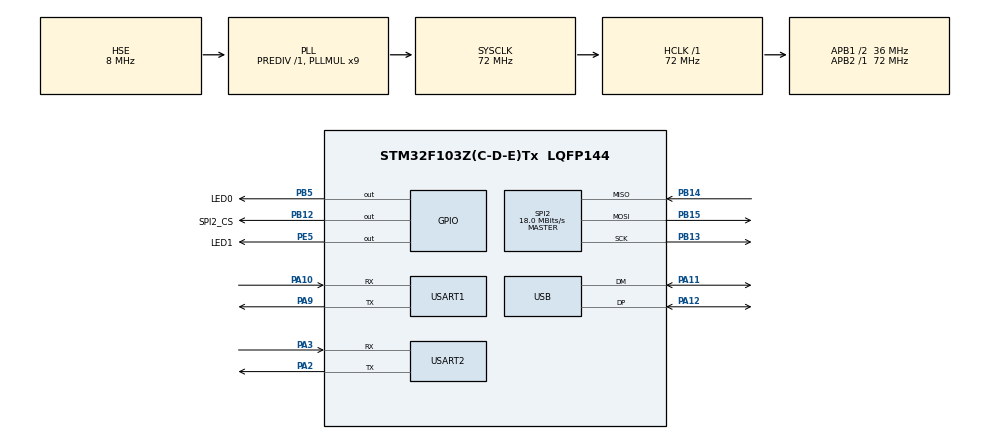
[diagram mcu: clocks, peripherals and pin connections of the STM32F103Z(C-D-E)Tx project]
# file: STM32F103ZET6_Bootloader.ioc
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Dma.Request0=USART1_RX
Dma.Request1=USART1_TX
Dma.Request2=USART2_RX
Dma.Request3=USART2_TX
Dma.USART1_RX.0.Direction=DMA_PERIPH_TO_MEMORY
Dma.USART1_RX.0.Instance=DMA1_Channel5
Dma.USART1_RX.0.MemDataAlignment=DMA_MDATAALIGN_BYTE
Dma.USART1_RX.0.MemInc=DMA_MINC_ENABLE
Dma.USART1_RX.0.Mode=DMA_NORMAL
Dma.USART1_RX.0.PeriphDataAlignment=DMA_PDATAALIGN_BYTE
Dma.USART1_RX.0.PeriphInc=DMA_PINC_DISABLE
Dma.USART1_RX.0.Priority=DMA_PRIORITY_LOW
Dma.USART1_TX.1.Direction=DMA_MEMORY_TO_PERIPH
Dma.USART1_TX.1.Instance=DMA1_Channel4
Dma.USART1_TX.1.MemDataAlignment=DMA_MDATAALIGN_BYTE
Dma.USART1_TX.1.MemInc=DMA_MINC_ENABLE
Dma.USART1_TX.1.Mode=DMA_NORMAL
Dma.USART1_TX.1.PeriphDataAlignment=DMA_PDATAALIGN_BYTE
Dma.USART1_TX.1.PeriphInc=DMA_PINC_DISABLE
Dma.USART1_TX.1.Priority=DMA_PRIORITY_LOW
Dma.USART2_RX.2.Direction=DMA_PERIPH_TO_MEMORY
Dma.USART2_RX.2.Instance=DMA1_Channel6
Dma.USART2_RX.2.MemDataAlignment=DMA_MDATAALIGN_BYTE
Dma.USART2_RX.2.MemInc=DMA_MINC_ENABLE
Dma.USART2_RX.2.Mode=DMA_NORMAL
Dma.USART2_RX.2.PeriphDataAlignment=DMA_PDATAALIGN_BYTE
Dma.USART2_RX.2.PeriphInc=DMA_PINC_DISABLE
Dma.USART2_RX.2.Priority=DMA_PRIORITY_LOW
Dma.USART2_TX.3.Direction=DMA_MEMORY_TO_PERIPH
Dma.USART2_TX.3.Instance=DMA1_Channel7
Dma.USART2_TX.3.MemDataAlignment=DMA_MDATAALIGN_BYTE
Dma.USART2_TX.3.MemInc=DMA_MINC_ENABLE
Dma.USART2_TX.3.Mode=DMA_NORMAL
Dma.USART2_TX.3.PeriphDataAlignment=DMA_PDATAALIGN_BYTE
Dma.USART2_TX.3.PeriphInc=DMA_PINC_DISABLE
Dma.USART2_TX.3.Priority=DMA_PRIORITY_LOW
FREERTOS.Tasks01=defaultTask,24,3072,StartDefaultTask,Default,NULL,Static,defaultTaskBuffer,defaultTaskControlBlock
FREERTOS.configTOTAL_HEAP_SIZE=5120
Mcu.Family=STM32F1
Mcu.Name=STM32F103Z(C-D-E)Tx
Mcu.Package=LQFP144
NVIC.DMA1_Channel4_IRQn=true\:5\:0\:false\:false\:true\:true\:false\:true
NVIC.DMA1_Channel5_IRQn=true\:5\:0\:false\:false\:true\:true\:false\:true
NVIC.DMA1_Channel6_IRQn=true\:5\:0\:false\:false\:true\:true\:false\:true
NVIC.DMA1_Channel7_IRQn=true\:5\:0\:false\:false\:true\:true\:false\:true
NVIC.PriorityGroup=NVIC_PRIORITYGROUP_4
NVIC.SPI2_IRQn=true\:5\:0\:false\:false\:true\:true\:true\:true
NVIC.TIM1_UP_IRQn=true\:0\:0\:false\:false\:true\:false\:false\:true
NVIC.TimeBase=TIM1_UP_IRQn
NVIC.TimeBaseIP=TIM1
NVIC.USART1_IRQn=true\:5\:0\:false\:false\:true\:true\:true\:true
NVIC.USART2_IRQn=true\:5\:0\:false\:false\:true\:true\:true\:true
NVIC.USB_LP_CAN1_RX0_IRQn=true\:5\:0\:false\:false\:true\:true\:false\:true
OSC_IN.Mode=HSE-External-Oscillator
OSC_IN.Signal=RCC_OSC_IN
OSC_OUT.Mode=HSE-External-Oscillator
OSC_OUT.Signal=RCC_OSC_OUT
PA10.GPIO_PuPd=GPIO_PULLUP
PA10.Mode=Asynchronous
PA10.Signal=USART1_RX
PA11.Mode=Device
PA11.Signal=USB_DM
PA12.Mode=Device
PA12.Signal=USB_DP
PA13.Mode=JTAG_5_pins
PA13.Signal=SYS_JTMS-SWDIO
PA14.Mode=JTAG_5_pins
PA14.Signal=SYS_JTCK-SWCLK
PA15.Mode=JTAG_5_pins
PA15.Signal=SYS_JTDI
PA2.Mode=Asynchronous
PA2.Signal=USART2_TX
PA3.GPIO_PuPd=GPIO_PULLUP
PA3.Mode=Asynchronous
PA3.Signal=USART2_RX
PA9.Mode=Asynchronous
PA9.Signal=USART1_TX
PB12.GPIO_Label=SPI2_CS
PB12.Signal=GPIO_Output
PB13.Mode=Full_Duplex_Master
PB13.Signal=SPI2_SCK
PB14.Mode=Full_Duplex_Master
PB14.Signal=SPI2_MISO
PB15.Mode=Full_Duplex_Master
PB15.Signal=SPI2_MOSI
PB3.Mode=JTAG_5_pins
PB3.Signal=SYS_JTDO-TRACESWO
PB4.Mode=JTAG_5_pins
PB4.Signal=SYS_NJTRST
PB5.GPIO_Label=LED0
PB5.Signal=GPIO_Output
PC14-OSC32_IN.Mode=LSE-External-Oscillator
PC14-OSC32_IN.Signal=RCC_OSC32_IN
PC15-OSC32_OUT.Mode=LSE-External-Oscillator
PC15-OSC32_OUT.Signal=RCC_OSC32_OUT
PE5.GPIO_Label=LED1
PE5.Signal=GPIO_Output
ProjectManager.HeapSize=0x1000
ProjectManager.StackSize=0x5000
ProjectManager.TargetToolchain=EWARM V8.32
RCC.AHBFreq_Value=72000000
RCC.APB1CLKDivider=RCC_HCLK_DIV2
RCC.APB1Freq_Value=36000000
RCC.APB1TimFreq_Value=72000000
RCC.APB2Freq_Value=72000000
RCC.APB2TimFreq_Value=72000000
RCC.HCLKFreq_Value=72000000
RCC.PLLMUL=RCC_PLL_MUL9
RCC.SYSCLKFreq_VALUE=72000000
RCC.SYSCLKSource=RCC_SYSCLKSOURCE_PLLCLK
RCC.USBFreq_Value=48000000
RCC.USBPrescaler=RCC_USBCLKSOURCE_PLL_DIV1_5
RTC.Format=RTC_FORMAT_BIN
SPI2.CLKPhase=SPI_PHASE_2EDGE
SPI2.CLKPolarity=SPI_POLARITY_HIGH
SPI2.CalculateBaudRate=18.0 MBits/s
SPI2.Direction=SPI_DIRECTION_2LINES
SPI2.Mode=SPI_MODE_MASTER
SPI2.VirtualType=VM_MASTER
USART1.VirtualMode=VM_ASYNC
USART2.VirtualMode=VM_ASYNC
USB_DEVICE.CLASS_NAME_FS=CUSTOM_HID
USB_DEVICE.VirtualMode=CustomHid
USB_DEVICE.VirtualModeFS=Custom_Hid_FS
VP_FREERTOS_VS_CMSIS_V2.Mode=CMSIS_V2
VP_RTC_VS_RTC_Activate.Mode=RTC_Enabled
VP_RTC_VS_RTC_Calendar.Mode=RTC_Calendar
VP_SYS_VS_tim1.Mode=TIM1
VP_USB_DEVICE_VS_USB_DEVICE_CUSTOM_HID_FS.Mode=CUSTOM_HID_FS
board=custom

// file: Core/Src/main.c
/* USER CODE BEGIN Header */
/**
  ******************************************************************************
  * @file           : main.c
  * @brief          : Main program body
  ******************************************************************************
  * @attention
  *
  * <h2><center>&copy; Copyright (c) 2021 STMicroelectronics.
  * All rights reserved.</center></h2>
  *
  * This software component is licensed by ST under Ultimate Liberty license
  * SLA0044, the "License"; You may not use this file except in compliance with
  * the License. You may obtain a copy of the License at:
  *                             www.st.com/SLA0044
  *
  ******************************************************************************
  */
/* USER CODE END Header */
#include "main.h"
#include "cmsis_os.h"
#include "dma.h"
#include "rtc.h"
#include "spi.h"
#include "usart.h"
#include "usb_device.h"
#include "gpio.h"

void SystemClock_Config(void);
void MX_FREERTOS_Init(void);

int main(void)
{

  /* MCU Configuration--------------------------------------------------------*/

  /* Reset of all peripherals, Initializes the Flash interface and the Systick. */
  HAL_Init();

  /* Configure the system clock */
  SystemClock_Config();

  /* Initialize all configured peripherals */
  MX_GPIO_Init();
  MX_DMA_Init();
  MX_USART1_UART_Init();
  MX_RTC_Init();
  MX_SPI2_Init();
  MX_USART2_UART_Init();
  /* USER CODE BEGIN 2 */
  User_Main_Init();
  /* USER CODE END 2 */

  /* Init scheduler */
  osKernelInitialize();  /* Call init function for freertos objects (in freertos.c) */
  MX_FREERTOS_Init();
  /* Start scheduler */
  osKernelStart();

  /* We should never get here as control is now taken by the scheduler */
  /* Infinite loop */
  while (1)
  {

  }
}

void SystemClock_Config(void)
{
  RCC_OscInitTypeDef RCC_OscInitStruct = {0};
  RCC_ClkInitTypeDef RCC_ClkInitStruct = {0};
  RCC_PeriphCLKInitTypeDef PeriphClkInit = {0};

  /** Initializes the RCC Oscillators according to the specified parameters
  * in the RCC_OscInitTypeDef structure.
  */
  RCC_OscInitStruct.OscillatorType = RCC_OSCILLATORTYPE_LSI|RCC_OSCILLATORTYPE_HSE;
  RCC_OscInitStruct.HSEState = RCC_HSE_ON;
  RCC_OscInitStruct.HSEPredivValue = RCC_HSE_PREDIV_DIV1;
  RCC_OscInitStruct.HSIState = RCC_HSI_ON;
  RCC_OscInitStruct.LSIState = RCC_LSI_ON;
  RCC_OscInitStruct.PLL.PLLState = RCC_PLL_ON;
  RCC_OscInitStruct.PLL.PLLSource = RCC_PLLSOURCE_HSE;
  RCC_OscInitStruct.PLL.PLLMUL = RCC_PLL_MUL9;
  if (HAL_RCC_OscConfig(&RCC_OscInitStruct) != HAL_OK)
  {
    Error_Handler();
  }
  /** Initializes the CPU, AHB and APB buses clocks
  */
  RCC_ClkInitStruct.ClockType = RCC_CLOCKTYPE_HCLK|RCC_CLOCKTYPE_SYSCLK
                              |RCC_CLOCKTYPE_PCLK1|RCC_CLOCKTYPE_PCLK2;
  RCC_ClkInitStruct.SYSCLKSource = RCC_SYSCLKSOURCE_PLLCLK;
  RCC_ClkInitStruct.AHBCLKDivider = RCC_SYSCLK_DIV1;
  RCC_ClkInitStruct.APB1CLKDivider = RCC_HCLK_DIV2;
  RCC_ClkInitStruct.APB2CLKDivider = RCC_HCLK_DIV1;

  if (HAL_RCC_ClockConfig(&RCC_ClkInitStruct, FLASH_LATENCY_2) != HAL_OK)
  {
    Error_Handler();
  }
  PeriphClkInit.PeriphClockSelection = RCC_PERIPHCLK_RTC|RCC_PERIPHCLK_USB;
  PeriphClkInit.RTCClockSelection = RCC_RTCCLKSOURCE_LSI;
  PeriphClkInit.UsbClockSelection = RCC_USBCLKSOURCE_PLL_DIV1_5;
  if (HAL_RCCEx_PeriphCLKConfig(&PeriphClkInit) != HAL_OK)
  {
    Error_Handler();
  }
}

 /**
  * @brief  Period elapsed callback in non blocking mode
  * @note   This function is called  when TIM1 interrupt took place, inside
  * HAL_TIM_IRQHandler(). It makes a direct call to HAL_IncTick() to increment
  * a global variable "uwTick" used as application time base.
  * @param  htim : TIM handle
  * @retval None
  */
void HAL_TIM_PeriodElapsedCallback(TIM_HandleTypeDef *htim)
{
  if (htim->Instance == TIM1) {
    HAL_IncTick();
  }
}

void Error_Handler(void)
{
  __disable_irq();
  while (1)
  {
  }
}

/************************ (C) COPYRIGHT STMicroelectronics *****END OF FILE****/

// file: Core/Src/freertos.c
/* USER CODE BEGIN Header */
/**
  ******************************************************************************
  * File Name          : freertos.c
  * Description        : Code for freertos applications
  ******************************************************************************
  * @attention
  *
  * <h2><center>&copy; Copyright (c) 2021 STMicroelectronics.
  * All rights reserved.</center></h2>
  *
  * This software component is licensed by ST under Ultimate Liberty license
  * SLA0044, the "License"; You may not use this file except in compliance with
  * the License. You may obtain a copy of the License at:
  *                             www.st.com/SLA0044
  *
  ******************************************************************************
  */
/* USER CODE END Header */

#include "FreeRTOS.h"
#include "task.h"
#include "main.h"
#include "cmsis_os.h"

typedef StaticTask_t osStaticThreadDef_t;

/* Definitions for defaultTask */
osThreadId_t defaultTaskHandle;
uint32_t defaultTaskBuffer[ 3072 ];
osStaticThreadDef_t defaultTaskControlBlock;
const osThreadAttr_t defaultTask_attributes = {
  .name = "defaultTask",
  .cb_mem = &defaultTaskControlBlock,
  .cb_size = sizeof(defaultTaskControlBlock),
  .stack_mem = &defaultTaskBuffer[0],
  .stack_size = sizeof(defaultTaskBuffer),
  .priority = (osPriority_t) osPriorityNormal,
};

void StartDefaultTask(void *argument);

extern void MX_USB_DEVICE_Init(void);
void MX_FREERTOS_Init(void); /* (MISRA C 2004 rule 8.1) */

void MX_FREERTOS_Init(void) {

  /* Create the thread(s) */
  /* creation of defaultTask */
  defaultTaskHandle = osThreadNew(StartDefaultTask, NULL, &defaultTask_attributes);

}

void StartDefaultTask(void *argument)
{
  /* init code for USB_DEVICE */
  MX_USB_DEVICE_Init();
  /* USER CODE BEGIN StartDefaultTask */
    /*start this must be first.*/
  /*注册接口初始�?*/
  Register_Port_Init();
  while(Register_Port_Start() == false);

  /*bl接口初始�?*/
  Bootloader_Port_Init();

  /*Easylogger初始�?*/
  EasyLog_Init();
  Test_LOG_Func();

  /*Shell初始�?*/
  Shell_Port_Init();
  /* Infinite loop */
  for(;;)
  {
    User_Main_Task_Start();
    osDelay(1);
  }
  /* USER CODE END StartDefaultTask */
}

/************************ (C) COPYRIGHT STMicroelectronics *****END OF FILE****/
